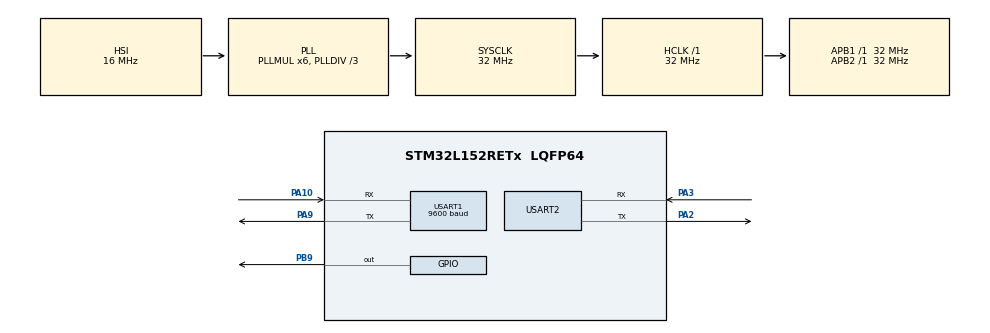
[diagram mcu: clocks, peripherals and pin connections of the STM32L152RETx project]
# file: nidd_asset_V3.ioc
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Dma.Request0=USART1_RX
Dma.USART1_RX.0.Direction=DMA_PERIPH_TO_MEMORY
Dma.USART1_RX.0.Instance=DMA1_Channel5
Dma.USART1_RX.0.MemDataAlignment=DMA_MDATAALIGN_BYTE
Dma.USART1_RX.0.MemInc=DMA_MINC_ENABLE
Dma.USART1_RX.0.Mode=DMA_NORMAL
Dma.USART1_RX.0.PeriphDataAlignment=DMA_PDATAALIGN_BYTE
Dma.USART1_RX.0.PeriphInc=DMA_PINC_DISABLE
Dma.USART1_RX.0.Priority=DMA_PRIORITY_MEDIUM
IWDG.Prescaler=IWDG_PRESCALER_256
IWDG.Reload=1444
Mcu.Family=STM32L1
Mcu.Name=STM32L152RETx
Mcu.Package=LQFP64
NVIC.DMA1_Channel5_IRQn=true\:0\:0\:false\:false\:true\:false\:true
NVIC.PriorityGroup=NVIC_PRIORITYGROUP_0
NVIC.TIM2_IRQn=true\:0\:0\:false\:false\:true\:true\:true
NVIC.USART1_IRQn=true\:0\:0\:false\:false\:true\:true\:true
NVIC.USART2_IRQn=true\:0\:0\:false\:false\:true\:true\:true
PA10.Mode=Asynchronous
PA10.Signal=USART1_RX
PA2.Mode=Asynchronous
PA2.Signal=USART2_TX
PA3.Mode=Asynchronous
PA3.Signal=USART2_RX
PA9.Mode=Asynchronous
PA9.Signal=USART1_TX
PB9.Signal=GPIO_Output
ProjectManager.HeapSize=0x200
ProjectManager.StackSize=0x400
ProjectManager.TargetToolchain=STM32CubeIDE
RCC.48MHZClocksFreq_Value=48000000
RCC.AHBFreq_Value=32000000
RCC.APB1Freq_Value=32000000
RCC.APB1TimFreq_Value=32000000
RCC.APB2Freq_Value=32000000
RCC.APB2TimFreq_Value=32000000
RCC.HCLKFreq_Value=32000000
RCC.HSE_VALUE=8000000
RCC.HSI_VALUE=16000000
RCC.LSE_VALUE=32768
RCC.MSI_VALUE=2097000
RCC.PLLDIV=RCC_PLL_DIV3
RCC.PLLMUL=RCC_PLL_MUL6
RCC.RTCClockSelectionVirtual=RCC_RTCCLKSOURCE_LSE
RCC.SYSCLKFreq_VALUE=32000000
RCC.SYSCLKSource=RCC_SYSCLKSOURCE_PLLCLK
RCC.USBOutput=48000000
RCC.VCOOutputFreq_Value=96000000
TIM2.Period=1000-1
TIM2.Prescaler=32000-1
USART1.BaudRate=9600
USART1.VirtualMode=VM_ASYNC
USART2.VirtualMode=VM_ASYNC
VP_IWDG_VS_IWDG.Mode=IWDG_Activate
VP_TIM2_VS_ClockSourceINT.Mode=Internal
board=NUCLEO-L152RE

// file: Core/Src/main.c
/* USER CODE BEGIN Header */
/**
  ******************************************************************************
  * @file           : main.c
  * @brief          : Main program body
  ******************************************************************************
  * @attention
  *
  * Copyright (c) 2025 STMicroelectronics.
  * All rights reserved.
  *
  * This software is licensed under terms that can be found in the LICENSE file
  * in the root directory of this software component.
  * If no LICENSE file comes with this software, it is provided AS-IS.
  *
  ******************************************************************************
  */
/* USER CODE END Header */
#include "main.h"

/* USER CODE BEGIN Includes */

//// ==== Function Prototype ====
//void process_uart_data(uint8_t *data, uint16_t len);

/* USER CODE END Includes */

IWDG_HandleTypeDef hiwdg;

TIM_HandleTypeDef htim2;

UART_HandleTypeDef huart1;
UART_HandleTypeDef huart2;
DMA_HandleTypeDef hdma_usart1_rx;

void SystemClock_Config(void);
static void MX_GPIO_Init(void);
static void MX_DMA_Init(void);
static void MX_USART1_UART_Init(void);
static void MX_TIM2_Init(void);
static void MX_USART2_UART_Init(void);
static void MX_IWDG_Init(void);

/* USER CODE BEGIN 0 */

const char *start="**************CODE BEGINS--***************B\r\n";

////////////////////////////////////////////////////////

const char *GPS_ACTIVE = "AT+CGPS=1\r\n";
const char *GPS_ACTIVE_AGNSS = "AT+CGPSAGNSS=1\r\n";
//const char *GPS_ACTIVE_AGNSS = "AT\r\n";
const char *GPS_GET ="AT+CGPSGPOS=5\r\n";
//const char *GPS_GET ="AT+GPSPORT=1\r\n";
//const char *GPS_GET_STOP ="AT+GPSPORT=0\r\n";

int main_state_flag=0;
//int main_state_flag=10;

#define SLEEP_TIME 1 //in minute
int SLEEP_TIME_SEC = 60;
//int SLEEP_TIME_SEC = SLEEP_TIME * 60;

////////////////////////////////////////////////////////

/* USER CODE END 0 */

int main(void)
{

  /* MCU Configuration--------------------------------------------------------*/

  /* Reset of all peripherals, Initializes the Flash interface and the Systick. */
  HAL_Init();

  /* Configure the system clock */
  SystemClock_Config();

  /* Initialize all configured peripherals */
  MX_GPIO_Init();
  MX_DMA_Init();
  MX_USART1_UART_Init();
  MX_TIM2_Init();
  MX_USART2_UART_Init();
  MX_IWDG_Init();
  /* USER CODE BEGIN 2 */
  HAL_UART_Receive_DMA(&huart1, rx_buffer, RX_BUFFER_SIZE);
  __HAL_UART_ENABLE_IT(&huart1, UART_IT_IDLE);  // Enable IDLE line detection
  HAL_TIM_Base_Start_IT(&htim2); //to start timer
  HAL_UART_Transmit(&huart2, (uint8_t *)start, strlen(start), 200);

  HAL_UART_Transmit(&huart1, (uint8_t *)"AT\r\n", strlen("AT\r\n"), 200);
  HAL_Delay(2000);
 // HAL_UART_Transmit(&huart1, (uint8_t *)"ATE\r\n", strlen("ATE\r\n"), 200);

  /* USER CODE END 2 */

  /* Infinite loop */

 mqtt_state = MQTT_STATE_CREATE;
 gps_state = GPS_STATE_ACTIVATE;
 sleep_state= GNSS_DISCONNECT;

 //******************************************
   NETWORK_SET_UP(); //THIS FUNCTION CONNECT TO NETWORK

   //USB_ACTIVE();
 // USB_SLEEP_MODE();
  /* USER CODE BEGIN WHILE */
 //main_state_flag = 2;
  while (1)
  {
	  if(main_state_flag == 0)
	  {
		  gps_data_get();
		  HAL_Delay(500);
	  }
	  else if(main_state_flag == 1)
	  {
		  mqtt_machine();
	  }
	  else if(main_state_flag == 2)
	  {
		  Sleep();

	  }
	  else if(main_state_flag == 3)
	  {
		  Wake_UP();

	  }

         ///////////////////////////////////////////////
	  if(strstr(rx_buffer , "+CME ERROR") != NULL)   //bug fixing CME ERROR
	  	 {
		    error_restart++;

	  	 }
	  else if(strstr(rx_buffer , "OK") != NULL)
	  {
		  error_restart = 0;
	  }

  }
  /* USER CODE END 3 */
}

void SystemClock_Config(void)
{
  RCC_OscInitTypeDef RCC_OscInitStruct = {0};
  RCC_ClkInitTypeDef RCC_ClkInitStruct = {0};

  /** Configure the main internal regulator output voltage
  */
  __HAL_PWR_VOLTAGESCALING_CONFIG(PWR_REGULATOR_VOLTAGE_SCALE1);
  /** Initializes the RCC Oscillators according to the specified parameters
  * in the RCC_OscInitTypeDef structure.
  */
  RCC_OscInitStruct.OscillatorType = RCC_OSCILLATORTYPE_HSI|RCC_OSCILLATORTYPE_LSI;
  RCC_OscInitStruct.HSIState = RCC_HSI_ON;
  RCC_OscInitStruct.HSICalibrationValue = RCC_HSICALIBRATION_DEFAULT;
  RCC_OscInitStruct.LSIState = RCC_LSI_ON;
  RCC_OscInitStruct.PLL.PLLState = RCC_PLL_ON;
  RCC_OscInitStruct.PLL.PLLSource = RCC_PLLSOURCE_HSI;
  RCC_OscInitStruct.PLL.PLLMUL = RCC_PLL_MUL6;
  RCC_OscInitStruct.PLL.PLLDIV = RCC_PLL_DIV3;
  if (HAL_RCC_OscConfig(&RCC_OscInitStruct) != HAL_OK)
  {
    Error_Handler();
  }
  /** Initializes the CPU, AHB and APB buses clocks
  */
  RCC_ClkInitStruct.ClockType = RCC_CLOCKTYPE_HCLK|RCC_CLOCKTYPE_SYSCLK
                              |RCC_CLOCKTYPE_PCLK1|RCC_CLOCKTYPE_PCLK2;
  RCC_ClkInitStruct.SYSCLKSource = RCC_SYSCLKSOURCE_PLLCLK;
  RCC_ClkInitStruct.AHBCLKDivider = RCC_SYSCLK_DIV1;
  RCC_ClkInitStruct.APB1CLKDivider = RCC_HCLK_DIV1;
  RCC_ClkInitStruct.APB2CLKDivider = RCC_HCLK_DIV1;

  if (HAL_RCC_ClockConfig(&RCC_ClkInitStruct, FLASH_LATENCY_1) != HAL_OK)
  {
    Error_Handler();
  }
}

static void MX_IWDG_Init(void)
{

  hiwdg.Instance = IWDG;
  hiwdg.Init.Prescaler = IWDG_PRESCALER_256;
  hiwdg.Init.Reload = 1444;
  if (HAL_IWDG_Init(&hiwdg) != HAL_OK)
  {
    Error_Handler();
  }

}

static void MX_TIM2_Init(void)
{

  TIM_ClockConfigTypeDef sClockSourceConfig = {0};
  TIM_MasterConfigTypeDef sMasterConfig = {0};

  htim2.Instance = TIM2;
  htim2.Init.Prescaler = 32000-1;
  htim2.Init.CounterMode = TIM_COUNTERMODE_UP;
  htim2.Init.Period = 1000-1;
  htim2.Init.ClockDivision = TIM_CLOCKDIVISION_DIV1;
  htim2.Init.AutoReloadPreload = TIM_AUTORELOAD_PRELOAD_DISABLE;
  if (HAL_TIM_Base_Init(&htim2) != HAL_OK)
  {
    Error_Handler();
  }
  sClockSourceConfig.ClockSource = TIM_CLOCKSOURCE_INTERNAL;
  if (HAL_TIM_ConfigClockSource(&htim2, &sClockSourceConfig) != HAL_OK)
  {
    Error_Handler();
  }
  sMasterConfig.MasterOutputTrigger = TIM_TRGO_RESET;
  sMasterConfig.MasterSlaveMode = TIM_MASTERSLAVEMODE_DISABLE;
  if (HAL_TIMEx_MasterConfigSynchronization(&htim2, &sMasterConfig) != HAL_OK)
  {
    Error_Handler();
  }

}

static void MX_USART1_UART_Init(void)
{

  huart1.Instance = USART1;
  huart1.Init.BaudRate = 9600;
  huart1.Init.WordLength = UART_WORDLENGTH_8B;
  huart1.Init.StopBits = UART_STOPBITS_1;
  huart1.Init.Parity = UART_PARITY_NONE;
  huart1.Init.Mode = UART_MODE_TX_RX;
  huart1.Init.HwFlowCtl = UART_HWCONTROL_NONE;
  huart1.Init.OverSampling = UART_OVERSAMPLING_16;
  if (HAL_UART_Init(&huart1) != HAL_OK)
  {
    Error_Handler();
  }

}

static void MX_USART2_UART_Init(void)
{

  huart2.Instance = USART2;
  huart2.Init.BaudRate = 115200;
  huart2.Init.WordLength = UART_WORDLENGTH_8B;
  huart2.Init.StopBits = UART_STOPBITS_1;
  huart2.Init.Parity = UART_PARITY_NONE;
  huart2.Init.Mode = UART_MODE_TX_RX;
  huart2.Init.HwFlowCtl = UART_HWCONTROL_NONE;
  huart2.Init.OverSampling = UART_OVERSAMPLING_16;
  if (HAL_UART_Init(&huart2) != HAL_OK)
  {
    Error_Handler();
  }

}

static void MX_DMA_Init(void)
{

  /* DMA controller clock enable */
  __HAL_RCC_DMA1_CLK_ENABLE();

  /* DMA interrupt init */
  /* DMA1_Channel5_IRQn interrupt configuration */
  HAL_NVIC_SetPriority(DMA1_Channel5_IRQn, 0, 0);
  HAL_NVIC_EnableIRQ(DMA1_Channel5_IRQn);

}

static void MX_GPIO_Init(void)
{
  GPIO_InitTypeDef GPIO_InitStruct = {0};

  /* GPIO Ports Clock Enable */
  __HAL_RCC_GPIOA_CLK_ENABLE();
  __HAL_RCC_GPIOB_CLK_ENABLE();

  /*Configure GPIO pin Output Level */
  HAL_GPIO_WritePin(GPIOB, GPIO_PIN_9, GPIO_PIN_RESET);

  /*Configure GPIO pin : PB9 */
  GPIO_InitStruct.Pin = GPIO_PIN_9;
  GPIO_InitStruct.Mode = GPIO_MODE_OUTPUT_PP;
  GPIO_InitStruct.Pull = GPIO_NOPULL;
  GPIO_InitStruct.Speed = GPIO_SPEED_FREQ_LOW;
  HAL_GPIO_Init(GPIOB, &GPIO_InitStruct);

}

void Error_Handler(void)
{
  __disable_irq();
  while (1)
  {
  }
}
